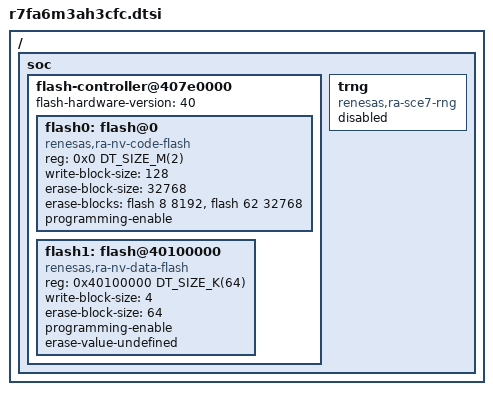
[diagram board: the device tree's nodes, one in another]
/*
 * Copyright (c) 2024-2025 Renesas Electronics Corporation
 *
 * SPDX-License-Identifier: Apache-2.0
 */

#include <arm/renesas/ra/ra6/r7fa6m3ax.dtsi>

/ {
	soc {
		flash-controller@407e0000 {
			flash-hardware-version = <40>;
			#erase-block-cells = <2>;

			flash0: flash@0 {
				compatible = "renesas,ra-nv-code-flash";
				reg = <0x0 DT_SIZE_M(2)>;
				write-block-size = <128>;
				erase-block-size = <32768>;
				erase-blocks = <&flash 8 8192>, <&flash 62 32768>;
				programming-enable;
			};

			flash1: flash@40100000 {
				compatible = "renesas,ra-nv-data-flash";
				reg = <0x40100000 DT_SIZE_K(64)>;
				write-block-size = <4>;
				erase-block-size = <64>;
				programming-enable;
				erase-value-undefined;
			};
		};

		trng: trng {
			compatible = "renesas,ra-sce7-rng";
			status = "disabled";
		};
	};
};
